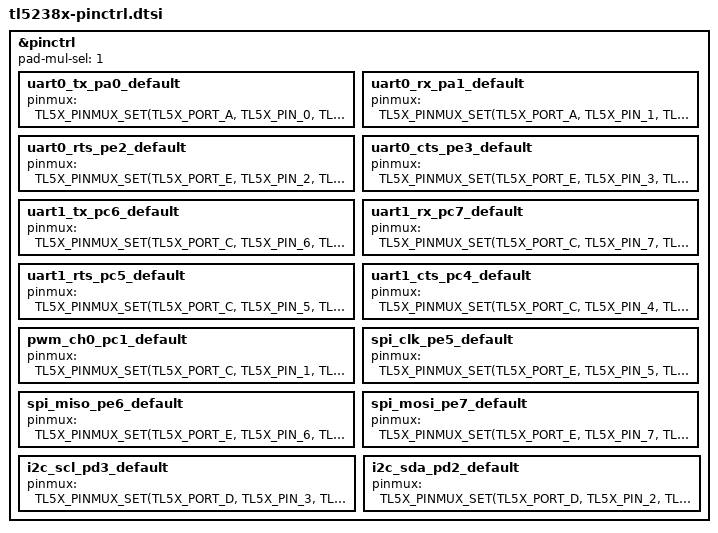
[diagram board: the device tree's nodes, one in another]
/*
 * Copyright (c) 2025 Telink Semiconductor
 *
 * SPDX-License-Identifier: Apache-2.0
 */

#include <zephyr/dt-bindings/pinctrl/tl523x-pinctrl.h>

&pinctrl {
	/* Set pad-mul-sel register value.
	 * Note: Pins functions below (pinmux = <...>) depend on this value.
	 */
	pad-mul-sel = <1>;

	uart0_tx_pa0_default: uart0_tx_pa0_default {
		pinmux = <TL5X_PINMUX_SET(TL5X_PORT_A, TL5X_PIN_0, TL523X_FUNC_UART0_RTX_IO)>;
	};
	uart0_rx_pa1_default: uart0_rx_pa1_default {
		pinmux = <TL5X_PINMUX_SET(TL5X_PORT_A, TL5X_PIN_1, TL523X_FUNC_UART0_RX_I)>;
	};
	uart0_rts_pe2_default: uart0_rts_pe2_default {
		pinmux = <TL5X_PINMUX_SET(TL5X_PORT_E, TL5X_PIN_2, TL523X_FUNC_UART0_RTS)>;
	};
	uart0_cts_pe3_default: uart0_cts_pe3_default {
		pinmux = <TL5X_PINMUX_SET(TL5X_PORT_E, TL5X_PIN_3, TL523X_FUNC_UART0_CTS_I)>;
	};

	uart1_tx_pc6_default: uart1_tx_pc6_default {
		pinmux = <TL5X_PINMUX_SET(TL5X_PORT_C, TL5X_PIN_6, TL523X_FUNC_UART1_RTX_IO)>;
	};
	uart1_rx_pc7_default: uart1_rx_pc7_default {
		pinmux = <TL5X_PINMUX_SET(TL5X_PORT_C, TL5X_PIN_7, TL523X_FUNC_UART1_RX_I)>;
	};
	uart1_rts_pc5_default: uart1_rts_pc5_default {
		pinmux = <TL5X_PINMUX_SET(TL5X_PORT_C, TL5X_PIN_5, TL523X_FUNC_UART1_RTS)>;
	};
	uart1_cts_pc4_default: uart1_cts_pc4_default {
		pinmux = <TL5X_PINMUX_SET(TL5X_PORT_C, TL5X_PIN_4, TL523X_FUNC_UART1_CTS_I)>;
	};

	/* PWM Channel 0 (PE4) */

	pwm_ch0_pc1_default: pwm_ch0_pc1_default {
		pinmux = <TL5X_PINMUX_SET(TL5X_PORT_C, TL5X_PIN_1, TL523X_FUNC_PWM0)>;
	};

	spi_clk_pe5_default: spi_clk_pe5_default {
		pinmux = <TL5X_PINMUX_SET(TL5X_PORT_E, TL5X_PIN_5, TL523X_FUNC_SPI_CK_IO)>;
	};
	spi_miso_pe6_default: spi_miso_pe6_default {
		pinmux = <TL5X_PINMUX_SET(TL5X_PORT_E, TL5X_PIN_6, TL523X_FUNC_SPI_MISO_IO)>;
	};
	spi_mosi_pe7_default: spi_mosi_pe7_default {
		pinmux = <TL5X_PINMUX_SET(TL5X_PORT_E, TL5X_PIN_7, TL523X_FUNC_SPI_MOSI_IO)>;
	};

	/* Define I2C pins: SCL(PD3), SDA(PD2) */

	i2c_scl_pd3_default: i2c_scl_pd3_default {
		pinmux = <TL5X_PINMUX_SET(TL5X_PORT_D, TL5X_PIN_3, TL523X_FUNC_I2C_SCL_IO)>;
	};
	i2c_sda_pd2_default: i2c_sda_pd2_default {
		pinmux = <TL5X_PINMUX_SET(TL5X_PORT_D, TL5X_PIN_2, TL523X_FUNC_I2C_SDA_IO)>;
	};
};
